# STM32F030x8 register map
File version: 1.0
Registers are 32-bit, read-write, reset 0x0 unless marked. A register's access mark holds for its fields unless they carry their own. Offsets are from the block's base; [hi:lo] are bit positions; {n}, {i} and the like mark numbered series.

## SYSCFG — SysTem Configuration
Base 0x40010000
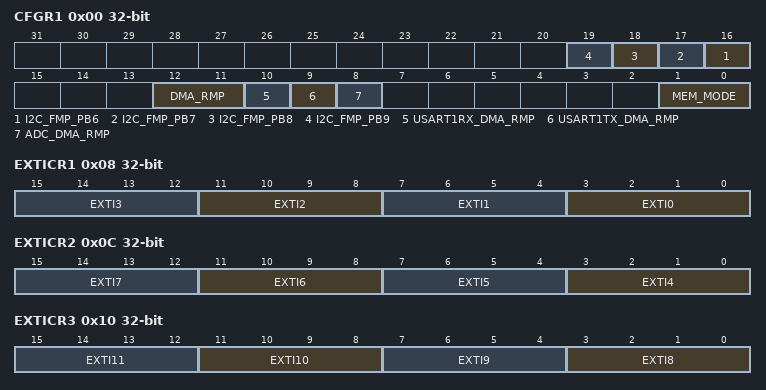
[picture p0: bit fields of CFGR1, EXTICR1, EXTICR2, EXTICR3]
0x00 CFGR1 — SYSCFG configuration register 1
  [n+10] I2C_FMP_PB{n} (n=6..9) — I2C PB{n} Fast mode plus
  [12:11] DMA_RMP — DMA remap mask
  [10] USART1RX_DMA_RMP — USART1 RX DMA remap
  [9] USART1TX_DMA_RMP — USART1 TX DMA remap
  [8] ADC_DMA_RMP — ADC DMA remap
    0=CH1 (ADC DMA request mapped on DMA channel 1U); 1=CH2 (ADC DMA request mapped on DMA channel 2U)
  [1:0] MEM_MODE — SYSCFG_Memory Remap Config
    0=FLASH (Main Flash memory mapped at 0x00000000); 1=SYSTEMFLASH (System Flash memory mapped at 0x00000000); 3=SRAM (Embedded SRAM mapped at 0x00000000)
0x08 EXTICR1 — SYSCFG external interrupt configuration register
  [4n+3:4n] EXTI{n} (n=0..3) — EXTI {n} configuration
0x0C EXTICR2 — SYSCFG external interrupt configuration register
  [4n-13:4n-16] EXTI{n} (n=4..7) — EXTI {n} configuration
0x10 EXTICR3 — SYSCFG external interrupt configuration register
  [4n-29:4n-32] EXTI{n} (n=8..11) — EXTI {n} configuration
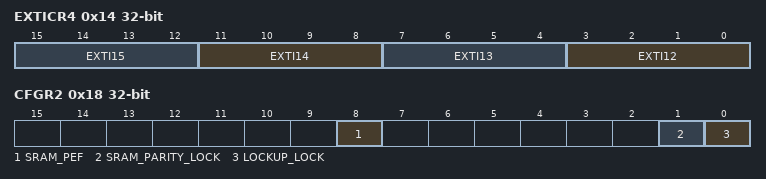
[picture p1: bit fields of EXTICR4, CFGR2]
0x14 EXTICR4 — SYSCFG external interrupt configuration register
  [4n-45:4n-48] EXTI{n} (n=12..15) — EXTI {n} configuration
0x18 CFGR2 — SYSCFG configuration register 2
  [8] SRAM_PEF — SRAM Parity error flag
  [1] SRAM_PARITY_LOCK — Enables and locks the SRAM_PARITY error signal with Break Input of TIMER1
  [0] LOCKUP_LOCK — Enables and locks the LOCKUP (Hardfault) output of CortexM0 with Break Input of TIMER1

## EXTI — External Interrupt/Event Controller
Base 0x40010400
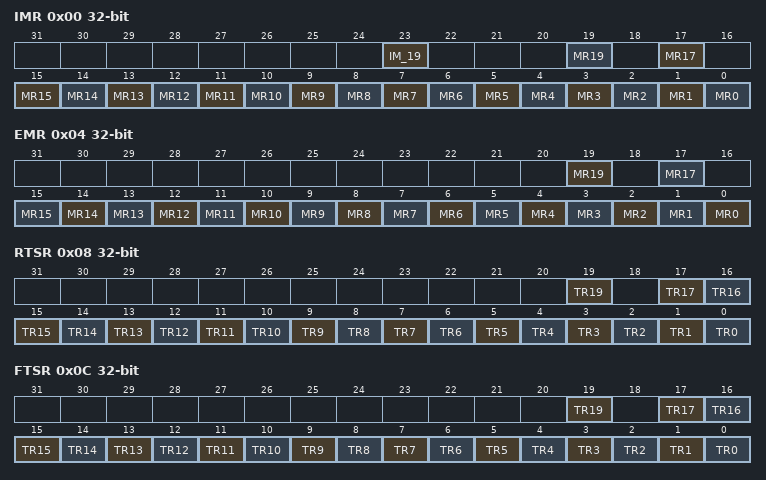
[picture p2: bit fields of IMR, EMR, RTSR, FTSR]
0x00 IMR — EXTI Interrupt mask register
  [23] IM_19 — Interrupt Mask All
  [19] MR19 — Interrupt Mask on line 19
  [17] MR17 — Interrupt Mask on line 17
  [n] MR{n} (n=0..15) — Interrupt Mask on line {n}
0x04 EMR — EXTI Event mask register
  [19] MR19 — Event Mask on line 19
  [17] MR17 — Event Mask on line 17
  [n] MR{n} (n=0..15) — Event Mask on line {n}
0x08 RTSR — EXTI Rising trigger selection register
  [19] TR19 — Rising trigger event configuration bit of line 19
  [n] TR{n} (n=0..17) — Rising trigger event configuration bit of line {n}
0x0C FTSR — EXTI Falling trigger selection register
  [19] TR19 — Falling trigger event configuration bit of line 19
  [n] TR{n} (n=0..17) — Falling trigger event configuration bit of line {n}
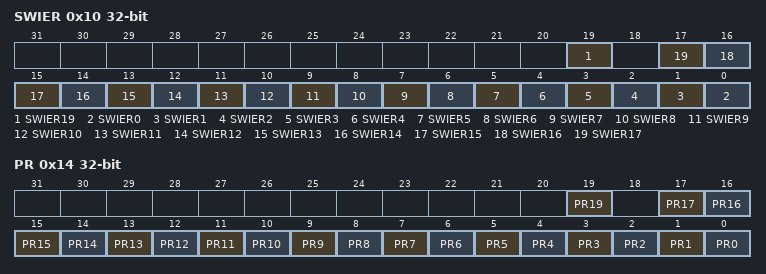
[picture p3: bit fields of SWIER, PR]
0x10 SWIER — EXTI Software interrupt event register
  [19] SWIER19 — Software Interrupt on line 19
  [n] SWIER{n} (n=0..17) — Software Interrupt on line {n}
0x14 PR — EXTI Pending register
  [19] PR19 — Pending bit 19
  [n] PR{n} (n=0..17) — Pending bit {n}

## ADC
Base 0x40012708
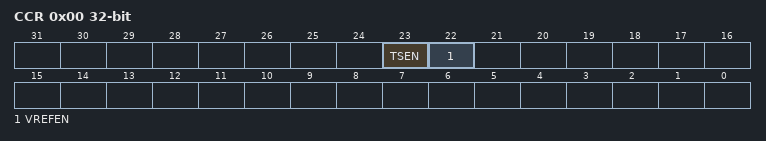
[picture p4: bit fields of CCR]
0x00 CCR — ADC common configuration register
  [23] TSEN — ADC internal path to temperature sensor enable
  [22] VREFEN — ADC internal path to VrefInt enable

## DBGMCU — Debug MCU
Base 0x40015800
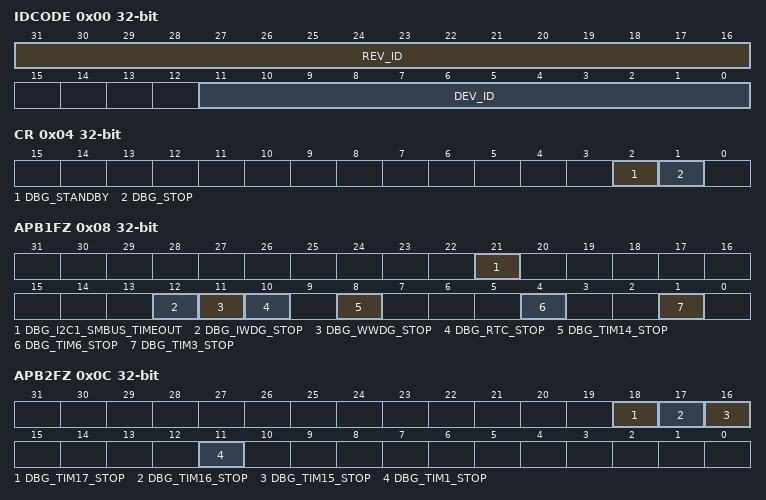
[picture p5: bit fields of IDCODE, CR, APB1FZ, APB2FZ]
0x00 IDCODE — MCU device ID code
  [31:16] REV_ID — REV_ID[15:0] bits (Revision Identifier)
  [11:0] DEV_ID — Device Identifier
0x04 CR — Debug MCU configuration register
  [2] DBG_STANDBY — Debug Standby mode
  [1] DBG_STOP — Debug Stop Mode
0x08 APB1FZ — Debug MCU APB1 freeze register
  [21] DBG_I2C1_SMBUS_TIMEOUT — I2C1 SMBUS timeout mode stopped when Core is halted
  [12] DBG_IWDG_STOP — Debug Independent Watchdog stopped when Core is halted
  [11] DBG_WWDG_STOP — Debug Window Watchdog stopped when Core is halted
  [10] DBG_RTC_STOP — RTC Calendar frozen when core is halted
  [8] DBG_TIM14_STOP — TIM14 counter stopped when core is halted
  [4] DBG_TIM6_STOP — TIM6 counter stopped when core is halted
  [1] DBG_TIM3_STOP — TIM3 counter stopped when core is halted
0x0C APB2FZ — Debug MCU APB2 freeze register
  [18] DBG_TIM17_STOP — TIM17 counter stopped when core is halted
  [17] DBG_TIM16_STOP — TIM16 counter stopped when core is halted
  [16] DBG_TIM15_STOP — TIM15 counter stopped when core is halted
  [11] DBG_TIM1_STOP — TIM1 counter stopped when core is halted
